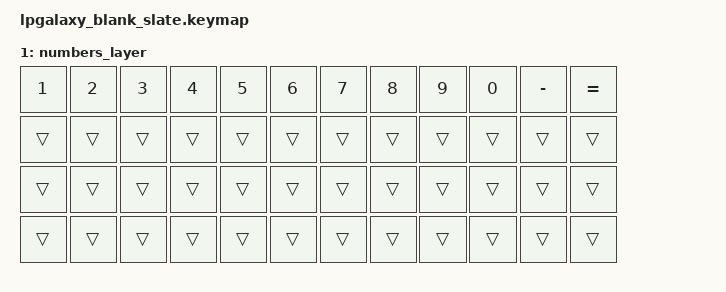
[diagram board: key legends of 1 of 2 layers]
/*
 * Copyright (c) 2022 Pete Johanson
 *
 * SPDX-License-Identifier: MIT
 */

#include <behaviors.dtsi>
#include <dt-bindings/zmk/keys.h>
#include <dt-bindings/zmk/bt.h>
#include <dt-bindings/zmk/outputs.h>

#define HOST_OS 2 // Mac OS
#include "zmk-helpers/helper.h"
// #include "zmk-helpers/key-labels/4x12.h"
// #include "./4x12mit.h"
#include "./4x12_2x2u.h"
#include "zmk-helpers/unicode-chars/french.dtsi"

#define QWERTY_BASE 1

// #define TBLE_ORTHO   1
// #define TBLE_MIT     1
#define TBLE_DUAL_2U 1

#define NAV_L 1
#define NUM_L 2
#define SYM_L 3

#define ___ &trans


// Using layer taps on thumbs, having quick tap as well helps w/ repeating space/backspaceg
&lt { quick_tap_ms = <200>; };

#define BT(n) BT_SEL n

/ {
    chosen {
       zmk,physical-layout =
#ifdef TBLE_DUAL_2U
                       &layout_ortho_4x12_2x2u;
#elif defined(TBLE_MIT)
                       &layout_ortho_4x12_1x2u;
#else
                       &layout_ortho_4x12_all1u;
#endif
    };
};

ZMK_LAYER(default_layer,
    //    ╭────────────────┬────────────────┬────────────────┬────────────────┬────────────────┬────────────────┬────────────────┬────────────────┬────────────────┬────────────────┬────────────────┬────────────────╮
            &kp ESC         &kp Q           &kp W           &kp E           &kp R           &kp T           &kp Y           &kp U           &kp I           &kp O           &kp P           // &kp LBKT        &kp RBKT         &kp BSLH
    //    ├────────────────┼────────────────┼────────────────┼────────────────┼────────────────┼────────────────┼────────────────┼────────────────┼────────────────┼────────────────┼────────────────┼────────────────┤
            &kp TAB         &kp A           &kp S           &kp D           &kp F           &kp G           &kp H           &kp J           &kp K           &kp L           &kp SEMI        &kp APOS
    //    ├────────────────┼────────────────┼────────────────┼────────────────┼────────────────┼────────────────┼────────────────┼────────────────┼────────────────┼────────────────┼────────────────┼────────────────┤
            &kp LSHFT       &kp Z           &kp X           &kp C           &kp V           &kp B           &kp N           &kp M           &kp COMMA       &kp DOT         &kp UP          &kp FSLH
    //    ├────────────────┼────────────────┼────────────────┼────────────────┼────────────────┴────────────────┼────────────────┴────────────────┼────────────────┼────────────────┼────────────────┼────────────────┤
            &kp LCTRL       &kp LALT        &kp LGUI        &none                       &kp SPACE                        &kp RET            &kp BSPC        &kp LEFT        &kp DOWN        &kp RIGHT
    //    ╰────────────────┴────────────────┴────────────────┴────────────────┴────────────────┴────────────────┴────────────────┴────────────────┴────────────────┴────────────────┴────────────────┴────────────────╯
)

ZMK_LAYER(numbers_layer,
    //    ╭────────────────┬────────────────┬────────────────┬────────────────┬────────────────┬────────────────┬────────────────┬────────────────┬────────────────┬────────────────┬────────────────┬────────────────╮
            &kp N1          &kp N2          &kp N3          &kp N4          &kp N5          &kp N6          &kp N7          &kp N8          &kp N9          &kp N0          &kp MINUS       &kp EQUAL
    //    ├────────────────┼────────────────┼────────────────┼────────────────┼────────────────┼────────────────┼────────────────┼────────────────┼────────────────┼────────────────┼────────────────┼────────────────┤
            ___             ___             ___             ___             ___             ___             ___             ___             ___             ___             ___             ___
    //    ├────────────────┼────────────────┼────────────────┼────────────────┼────────────────┼────────────────┼────────────────┼────────────────┼────────────────┼────────────────┼────────────────┼────────────────┤
            ___             ___             ___             ___             ___             ___             ___             ___             ___             ___             ___             ___
    //    ├────────────────┼────────────────┼────────────────┼────────────────┼────────────────┴────────────────┼────────────────┴────────────────┼────────────────┼────────────────┼────────────────┼────────────────┤
            ___             ___             ___             ___             ___             ___             ___             ___             ___             ___             ___             ___
    //    ╰────────────────┴────────────────┴────────────────┴────────────────┴────────────────┴────────────────┴────────────────┴────────────────┴────────────────┴────────────────┴────────────────┴────────────────╯
)
